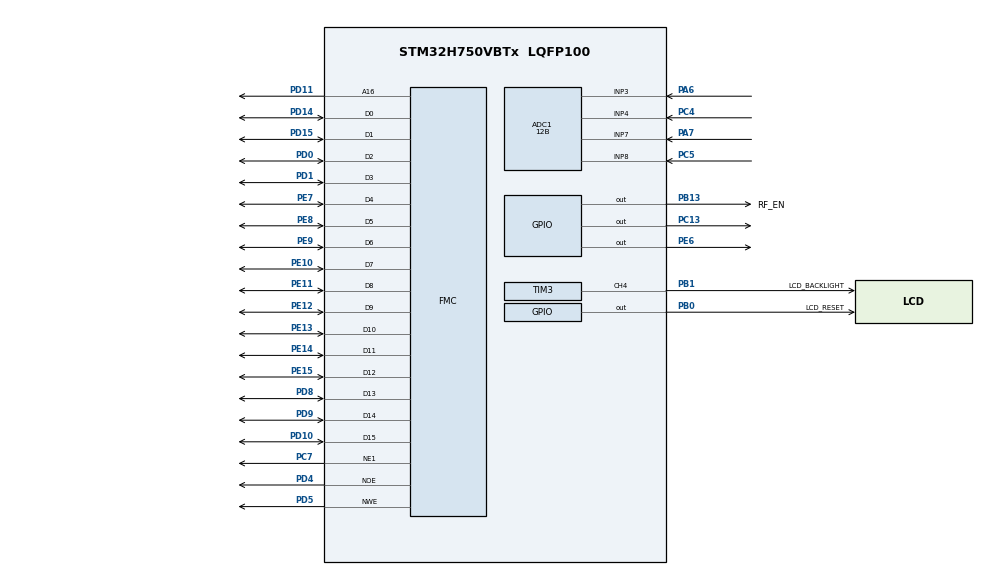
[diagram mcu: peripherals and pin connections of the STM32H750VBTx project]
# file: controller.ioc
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ADC1.Channel-0\#ChannelRegularConversion=ADC_CHANNEL_8
ADC1.Channel-1\#ChannelRegularConversion=ADC_CHANNEL_4
ADC1.Channel-2\#ChannelRegularConversion=ADC_CHANNEL_7
ADC1.Channel-3\#ChannelRegularConversion=ADC_CHANNEL_3
ADC1.ClockPrescaler=ADC_CLOCK_ASYNC_DIV2
ADC1.ContinuousConvMode=ENABLE
ADC1.ConversionDataManagement=ADC_CONVERSIONDATA_DMA_CIRCULAR
ADC1.NbrOfConversion=4
ADC1.NbrOfConversionFlag=1
ADC1.OffsetNumber-0\#ChannelRegularConversion=ADC_OFFSET_NONE
ADC1.OffsetNumber-1\#ChannelRegularConversion=ADC_OFFSET_NONE
ADC1.OffsetNumber-2\#ChannelRegularConversion=ADC_OFFSET_NONE
ADC1.OffsetNumber-3\#ChannelRegularConversion=ADC_OFFSET_NONE
ADC1.OffsetSignedSaturation-0\#ChannelRegularConversion=DISABLE
ADC1.Overrun=ADC_OVR_DATA_OVERWRITTEN
ADC1.Rank-0\#ChannelRegularConversion=1
ADC1.Rank-1\#ChannelRegularConversion=2
ADC1.Rank-2\#ChannelRegularConversion=3
ADC1.Rank-3\#ChannelRegularConversion=4
ADC1.Resolution=ADC_RESOLUTION_12B
ADC1.SamplingTime-0\#ChannelRegularConversion=ADC_SAMPLETIME_64CYCLES_5
ADC1.SamplingTime-1\#ChannelRegularConversion=ADC_SAMPLETIME_64CYCLES_5
ADC1.SamplingTime-2\#ChannelRegularConversion=ADC_SAMPLETIME_64CYCLES_5
ADC1.SamplingTime-3\#ChannelRegularConversion=ADC_SAMPLETIME_64CYCLES_5
ADC1.master=1
CORTEX_M7.AccessPermission_S-Cortex_Memory_Protection_Unit_Region1_Settings_S=MPU_REGION_FULL_ACCESS
CORTEX_M7.BaseAddress_S-Cortex_Memory_Protection_Unit_Region1_Settings_S=0x60000000
CORTEX_M7.DisableExec_S-Cortex_Memory_Protection_Unit_Region1_Settings_S=MPU_INSTRUCTION_ACCESS_DISABLE
CORTEX_M7.Enable_S-Cortex_Memory_Protection_Unit_Region1_Settings_S=MPU_REGION_ENABLE
CORTEX_M7.IsShareable_S-Cortex_Memory_Protection_Unit_Region1_Settings_S=MPU_ACCESS_SHAREABLE
CORTEX_M7.Size_S-Cortex_Memory_Protection_Unit_Region1_Settings_S=MPU_REGION_SIZE_256KB
CORTEX_M7.default_mode_Activation=1
Dma.ADC1.0.Direction=DMA_PERIPH_TO_MEMORY
Dma.ADC1.0.EventEnable=DISABLE
Dma.ADC1.0.FIFOMode=DMA_FIFOMODE_DISABLE
Dma.ADC1.0.Instance=DMA1_Stream0
Dma.ADC1.0.MemDataAlignment=DMA_MDATAALIGN_HALFWORD
Dma.ADC1.0.MemInc=DMA_MINC_ENABLE
Dma.ADC1.0.Mode=DMA_CIRCULAR
Dma.ADC1.0.PeriphDataAlignment=DMA_PDATAALIGN_HALFWORD
Dma.ADC1.0.PeriphInc=DMA_PINC_DISABLE
Dma.ADC1.0.Polarity=HAL_DMAMUX_REQ_GEN_RISING
Dma.ADC1.0.Priority=DMA_PRIORITY_MEDIUM
Dma.ADC1.0.RequestNumber=1
Dma.ADC1.0.SignalID=NONE
Dma.ADC1.0.SyncEnable=DISABLE
Dma.ADC1.0.SyncPolarity=HAL_DMAMUX_SYNC_NO_EVENT
Dma.ADC1.0.SyncRequestNumber=1
Dma.ADC1.0.SyncSignalID=NONE
Dma.Request0=ADC1
FMC.AddressSetupTime1=5
FMC.DataSetupTime1=110
FMC.ExtendedAddressSetupTime1=5
FMC.ExtendedDataSetupTime1=20
FMC.ExtendedMode1=FMC_EXTENDED_MODE_ENABLE
FREERTOS.Tasks01=defaultTask,24,128,StartDefaultTask,Default,NULL,Dynamic,NULL,NULL
Mcu.Family=STM32H7
Mcu.Name=STM32H750VBTx
Mcu.Package=LQFP100
NVIC.DMA1_Stream0_IRQn=true\:5\:0\:false\:false\:true\:true\:false\:true\:true
NVIC.PriorityGroup=NVIC_PRIORITYGROUP_4
NVIC.TIM6_DAC_IRQn=true\:15\:0\:false\:false\:true\:false\:false\:true\:true
NVIC.TimeBase=TIM6_DAC_IRQn
NVIC.TimeBaseIP=TIM6
PA13\ (JTMS/SWDIO).Mode=Serial_Wire
PA13\ (JTMS/SWDIO).Signal=DEBUG_JTMS-SWDIO
PA14\ (JTCK/SWCLK).Mode=Serial_Wire
PA14\ (JTCK/SWCLK).Signal=DEBUG_JTCK-SWCLK
PA6.Signal=ADCx_INP3
PA7.Signal=ADCx_INP7
PB0.GPIO_Label=LCD_RESET
PB0.Signal=GPIO_Output
PB1.GPIO_Label=LCD_BACKLIGHT
PB1.Signal=S_TIM3_CH4
PB13.GPIO_Label=RF_EN
PB13.Signal=GPIO_Output
PC13.Signal=GPIO_Output
PC14-OSC32_IN\ (OSC32_IN).Mode=LSE-External-Oscillator
PC14-OSC32_IN\ (OSC32_IN).Signal=RCC_OSC32_IN
PC15-OSC32_OUT\ (OSC32_OUT).Mode=LSE-External-Oscillator
PC15-OSC32_OUT\ (OSC32_OUT).Signal=RCC_OSC32_OUT
PC4.Signal=ADCx_INP4
PC5.Signal=ADCx_INP8
PC7.Mode=NorPsramChipSelect1_1
PC7.Signal=FMC_NE1
PD0.Signal=FMC_D2_DA2
PD1.Signal=FMC_D3_DA3
PD10.Signal=FMC_D15_DA15
PD11.Signal=FMC_A16_CLE
PD14.Signal=FMC_D0_DA0
PD15.Signal=FMC_D1_DA1
PD4.Signal=FMC_NOE
PD5.Signal=FMC_NWE
PD8.Signal=FMC_D13_DA13
PD9.Signal=FMC_D14_DA14
PE10.Signal=FMC_D7_DA7
PE11.Signal=FMC_D8_DA8
PE12.Signal=FMC_D9_DA9
PE13.Signal=FMC_D10_DA10
PE14.Signal=FMC_D11_DA11
PE15.Signal=FMC_D12_DA12
PE6.Signal=GPIO_Output
PE7.Signal=FMC_D4_DA4
PE8.Signal=FMC_D5_DA5
PE9.Signal=FMC_D6_DA6
PH0-OSC_IN\ (PH0).Mode=HSE-External-Oscillator
PH0-OSC_IN\ (PH0).Signal=RCC_OSC_IN
PH1-OSC_OUT\ (PH1).Mode=HSE-External-Oscillator
PH1-OSC_OUT\ (PH1).Signal=RCC_OSC_OUT
ProjectManager.HeapSize=0x200
ProjectManager.StackSize=0x400
ProjectManager.TargetToolchain=CMake
RCC.ADCFreq_Value=80000000
RCC.APB1Freq_Value=120000000
RCC.APB2Freq_Value=120000000
RCC.APB3Freq_Value=120000000
RCC.APB4Freq_Value=120000000
RCC.CortexFreq_Value=480000000
RCC.D1PPRE=RCC_APB3_DIV2
RCC.D2PPRE1=RCC_APB1_DIV2
RCC.D2PPRE2=RCC_APB2_DIV2
RCC.D3PPRE=RCC_APB4_DIV2
RCC.DIVM1=1
RCC.DIVM2=1
RCC.DIVN1=60
RCC.DIVN2=10
RCC.EnbaleCSS=true
RCC.HCLKFreq_Value=240000000
RCC.HPRE=RCC_HCLK_DIV2
RCC.HSE_VALUE=16000000
RCC.PLL2FRACN=0
RCC.PLL3FRACN=0
RCC.PLLFRACN=0
RCC.PLLSourceVirtual=RCC_PLLSOURCE_HSE
RCC.RTCClockSelection=RCC_RTCCLKSOURCE_LSE
RCC.SYSCLKFreq_VALUE=480000000
RCC.SYSCLKSource=RCC_SYSCLKSOURCE_PLLCLK
RCC.USBFreq_Value=480000000
SH.ADCx_INP3.0=ADC1_INP3,IN3-Single-Ended
SH.ADCx_INP4.0=ADC1_INP4,IN4-Single-Ended
SH.ADCx_INP7.0=ADC1_INP7,IN7-Single-Ended
SH.ADCx_INP8.0=ADC1_INP8,IN8-Single-Ended
SH.FMC_A16_CLE.0=FMC_A16,A16_1
SH.FMC_D0_DA0.0=FMC_D0,16b-d1
SH.FMC_D10_DA10.0=FMC_D10,16b-d1
SH.FMC_D11_DA11.0=FMC_D11,16b-d1
SH.FMC_D12_DA12.0=FMC_D12,16b-d1
SH.FMC_D13_DA13.0=FMC_D13,16b-d1
SH.FMC_D14_DA14.0=FMC_D14,16b-d1
SH.FMC_D15_DA15.0=FMC_D15,16b-d1
SH.FMC_D1_DA1.0=FMC_D1,16b-d1
SH.FMC_D2_DA2.0=FMC_D2,16b-d1
SH.FMC_D3_DA3.0=FMC_D3,16b-d1
SH.FMC_D4_DA4.0=FMC_D4,16b-d1
SH.FMC_D5_DA5.0=FMC_D5,16b-d1
SH.FMC_D6_DA6.0=FMC_D6,16b-d1
SH.FMC_D7_DA7.0=FMC_D7,16b-d1
SH.FMC_D8_DA8.0=FMC_D8,16b-d1
SH.FMC_D9_DA9.0=FMC_D9,16b-d1
SH.FMC_NOE.0=FMC_NOE,Lcd1
SH.FMC_NWE.0=FMC_NWE,Lcd1
SH.S_TIM3_CH4.0=TIM3_CH4,PWM Generation4 CH4
TIM3.AutoReloadPreload=TIM_AUTORELOAD_PRELOAD_ENABLE
TIM3.Channel-PWM\ Generation4\ CH4=TIM_CHANNEL_4
VP_FREERTOS_VS_CMSIS_V2.Mode=CMSIS_V2
VP_MEMORYMAP_VS_MEMORYMAP.Mode=CurAppReg
VP_SYS_VS_tim6.Mode=TIM6
board=custom

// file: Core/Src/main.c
/* USER CODE BEGIN Header */
/**
  ******************************************************************************
  * @file           : main.c
  * @brief          : Main program body
  ******************************************************************************
  * @attention
  *
  * Copyright (c) 2026 STMicroelectronics.
  * All rights reserved.
  *
  * This software is licensed under terms that can be found in the LICENSE file
  * in the root directory of this software component.
  * If no LICENSE file comes with this software, it is provided AS-IS.
  *
  ******************************************************************************
  */
/* USER CODE END Header */
#include "main.h"
#include "FreeRTOS.h"
#include "cmsis_os2.h"
#include "adc.h"
#include "dma.h"
#include "tim.h"
#include "gpio.h"
#include "fmc.h"

void SystemClock_Config(void);
static void MPU_Config(void);
void MX_FREERTOS_Init(void);

int main(void)
{

  /* MPU Configuration--------------------------------------------------------*/
  MPU_Config();

  /* MCU Configuration--------------------------------------------------------*/

  /* Reset of all peripherals, Initializes the Flash interface and the Systick. */
  HAL_Init();

  /* Configure the system clock */
  SystemClock_Config();

  /* Initialize all configured peripherals */
  MX_GPIO_Init();
  MX_DMA_Init();
  MX_TIM3_Init();
  MX_ADC1_Init();
  MX_FMC_Init();

  /* Init scheduler */
  osKernelInitialize();  /* Call init function for freertos objects (in cmsis_os2.c) */
  MX_FREERTOS_Init();

  /* Start scheduler */
  osKernelStart();

  /* We should never get here as control is now taken by the scheduler */

  /* Infinite loop */
  while (1)
  {

  }
}

void SystemClock_Config(void)
{
  RCC_OscInitTypeDef RCC_OscInitStruct = {0};
  RCC_ClkInitTypeDef RCC_ClkInitStruct = {0};

  /** Supply configuration update enable
  */
  HAL_PWREx_ConfigSupply(PWR_LDO_SUPPLY);

  /** Configure the main internal regulator output voltage
  */
  __HAL_PWR_VOLTAGESCALING_CONFIG(PWR_REGULATOR_VOLTAGE_SCALE0);

  while(!__HAL_PWR_GET_FLAG(PWR_FLAG_VOSRDY)) {}

  /** Initializes the RCC Oscillators according to the specified parameters
  * in the RCC_OscInitTypeDef structure.
  */
  RCC_OscInitStruct.OscillatorType = RCC_OSCILLATORTYPE_HSE;
  RCC_OscInitStruct.HSEState = RCC_HSE_ON;
  RCC_OscInitStruct.PLL.PLLState = RCC_PLL_ON;
  RCC_OscInitStruct.PLL.PLLSource = RCC_PLLSOURCE_HSE;
  RCC_OscInitStruct.PLL.PLLM = 1;
  RCC_OscInitStruct.PLL.PLLN = 60;
  RCC_OscInitStruct.PLL.PLLP = 2;
  RCC_OscInitStruct.PLL.PLLQ = 2;
  RCC_OscInitStruct.PLL.PLLR = 2;
  RCC_OscInitStruct.PLL.PLLRGE = RCC_PLL1VCIRANGE_3;
  RCC_OscInitStruct.PLL.PLLVCOSEL = RCC_PLL1VCOWIDE;
  RCC_OscInitStruct.PLL.PLLFRACN = 0;
  if (HAL_RCC_OscConfig(&RCC_OscInitStruct) != HAL_OK)
  {
    Error_Handler();
  }

  /** Initializes the CPU, AHB and APB buses clocks
  */
  RCC_ClkInitStruct.ClockType = RCC_CLOCKTYPE_HCLK|RCC_CLOCKTYPE_SYSCLK
                              |RCC_CLOCKTYPE_PCLK1|RCC_CLOCKTYPE_PCLK2
                              |RCC_CLOCKTYPE_D3PCLK1|RCC_CLOCKTYPE_D1PCLK1;
  RCC_ClkInitStruct.SYSCLKSource = RCC_SYSCLKSOURCE_PLLCLK;
  RCC_ClkInitStruct.SYSCLKDivider = RCC_SYSCLK_DIV1;
  RCC_ClkInitStruct.AHBCLKDivider = RCC_HCLK_DIV2;
  RCC_ClkInitStruct.APB3CLKDivider = RCC_APB3_DIV2;
  RCC_ClkInitStruct.APB1CLKDivider = RCC_APB1_DIV2;
  RCC_ClkInitStruct.APB2CLKDivider = RCC_APB2_DIV2;
  RCC_ClkInitStruct.APB4CLKDivider = RCC_APB4_DIV2;

  if (HAL_RCC_ClockConfig(&RCC_ClkInitStruct, FLASH_LATENCY_4) != HAL_OK)
  {
    Error_Handler();
  }

  /** Enables the Clock Security System
  */
  HAL_RCC_EnableCSS();
}

 /* MPU Configuration */

void MPU_Config(void)
{
  MPU_Region_InitTypeDef MPU_InitStruct = {0};

  /* Disables the MPU */
  HAL_MPU_Disable();

  /** Initializes and configures the Region and the memory to be protected
  */
  MPU_InitStruct.Enable = MPU_REGION_ENABLE;
  MPU_InitStruct.Number = MPU_REGION_NUMBER0;
  MPU_InitStruct.BaseAddress = 0x0;
  MPU_InitStruct.Size = MPU_REGION_SIZE_4GB;
  MPU_InitStruct.SubRegionDisable = 0x87;
  MPU_InitStruct.TypeExtField = MPU_TEX_LEVEL0;
  MPU_InitStruct.AccessPermission = MPU_REGION_NO_ACCESS;
  MPU_InitStruct.DisableExec = MPU_INSTRUCTION_ACCESS_DISABLE;
  MPU_InitStruct.IsShareable = MPU_ACCESS_SHAREABLE;
  MPU_InitStruct.IsCacheable = MPU_ACCESS_NOT_CACHEABLE;
  MPU_InitStruct.IsBufferable = MPU_ACCESS_NOT_BUFFERABLE;

  HAL_MPU_ConfigRegion(&MPU_InitStruct);

  /** Initializes and configures the Region and the memory to be protected
  */
  MPU_InitStruct.Number = MPU_REGION_NUMBER1;
  MPU_InitStruct.BaseAddress = 0x60000000;
  MPU_InitStruct.Size = MPU_REGION_SIZE_256KB;
  MPU_InitStruct.SubRegionDisable = 0x0;
  MPU_InitStruct.AccessPermission = MPU_REGION_FULL_ACCESS;

  HAL_MPU_ConfigRegion(&MPU_InitStruct);
  /* Enables the MPU */
  HAL_MPU_Enable(MPU_PRIVILEGED_DEFAULT);

}

void HAL_TIM_PeriodElapsedCallback(TIM_HandleTypeDef *htim)
{
  if (htim->Instance == TIM6)
  {
    HAL_IncTick();
  }
}

void Error_Handler(void)
{
  __disable_irq();
  while (1)
  {
  }
}

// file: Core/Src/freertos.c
/* USER CODE BEGIN Header */
/**
  ******************************************************************************
  * File Name          : freertos.c
  * Description        : Code for freertos applications
  ******************************************************************************
  * @attention
  *
  * Copyright (c) 2026 STMicroelectronics.
  * All rights reserved.
  *
  * This software is licensed under terms that can be found in the LICENSE file
  * in the root directory of this software component.
  * If no LICENSE file comes with this software, it is provided AS-IS.
  *
  ******************************************************************************
  */
/* USER CODE END Header */

#include "FreeRTOS.h"
#include "task.h"
#include "main.h"
#include "FreeRTOS.h"
#include "cmsis_os2.h"

/* USER CODE BEGIN Includes */
#include "init.h"
/* USER CODE END Includes */

/* Definitions for defaultTask */
osThreadId_t defaultTaskHandle;
const osThreadAttr_t defaultTask_attributes = {
  .name = "defaultTask",
  .stack_size = 128 * 4,
  .priority = (osPriority_t) osPriorityNormal,
};

void StartDefaultTask(void *argument);

void MX_FREERTOS_Init(void); /* (MISRA C 2004 rule 8.1) */

void MX_FREERTOS_Init(void) {
  /* USER CODE BEGIN Init */
  init();
  /* USER CODE END Init */

  /* Create the thread(s) */
  /* creation of defaultTask */
  defaultTaskHandle = osThreadNew(StartDefaultTask, NULL, &defaultTask_attributes);

}

void StartDefaultTask(void *argument)
{
  /* USER CODE BEGIN StartDefaultTask */
  osThreadExit();
  /* Infinite loop */
  for(;;)
  {
    osDelay(1);
  }
  /* USER CODE END StartDefaultTask */
}
